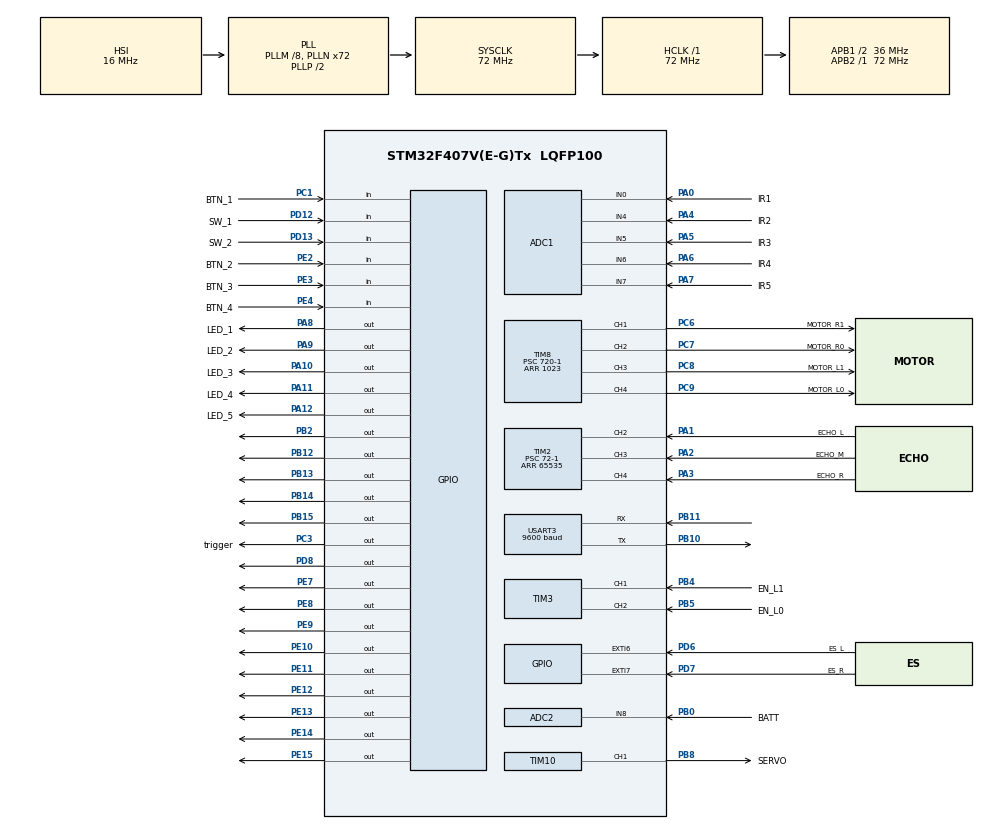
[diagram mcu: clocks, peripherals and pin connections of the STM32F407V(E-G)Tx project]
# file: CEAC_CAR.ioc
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ADC1.Channel-0\#ChannelRegularConversion=ADC_CHANNEL_0
ADC1.Channel-1\#ChannelRegularConversion=ADC_CHANNEL_4
ADC1.Channel-2\#ChannelRegularConversion=ADC_CHANNEL_5
ADC1.Channel-3\#ChannelRegularConversion=ADC_CHANNEL_6
ADC1.Channel-4\#ChannelRegularConversion=ADC_CHANNEL_7
ADC1.ContinuousConvMode=ENABLE
ADC1.NbrOfConversion=5
ADC1.NbrOfConversionFlag=1
ADC1.Rank-0\#ChannelRegularConversion=1
ADC1.Rank-1\#ChannelRegularConversion=2
ADC1.Rank-2\#ChannelRegularConversion=3
ADC1.Rank-3\#ChannelRegularConversion=4
ADC1.Rank-4\#ChannelRegularConversion=5
ADC1.SamplingTime-0\#ChannelRegularConversion=ADC_SAMPLETIME_3CYCLES
ADC1.SamplingTime-1\#ChannelRegularConversion=ADC_SAMPLETIME_3CYCLES
ADC1.SamplingTime-2\#ChannelRegularConversion=ADC_SAMPLETIME_3CYCLES
ADC1.SamplingTime-3\#ChannelRegularConversion=ADC_SAMPLETIME_3CYCLES
ADC1.SamplingTime-4\#ChannelRegularConversion=ADC_SAMPLETIME_3CYCLES
ADC1.master=1
ADC2.Channel-0\#ChannelRegularConversion=ADC_CHANNEL_8
ADC2.NbrOfConversionFlag=1
ADC2.Rank-0\#ChannelRegularConversion=1
ADC2.SamplingTime-0\#ChannelRegularConversion=ADC_SAMPLETIME_3CYCLES
Dma.ADC1.0.Direction=DMA_PERIPH_TO_MEMORY
Dma.ADC1.0.FIFOMode=DMA_FIFOMODE_DISABLE
Dma.ADC1.0.Instance=DMA2_Stream0
Dma.ADC1.0.MemDataAlignment=DMA_MDATAALIGN_HALFWORD
Dma.ADC1.0.MemInc=DMA_MINC_ENABLE
Dma.ADC1.0.Mode=DMA_CIRCULAR
Dma.ADC1.0.PeriphDataAlignment=DMA_PDATAALIGN_HALFWORD
Dma.ADC1.0.PeriphInc=DMA_PINC_DISABLE
Dma.ADC1.0.Priority=DMA_PRIORITY_LOW
Dma.Request0=ADC1
Mcu.Family=STM32F4
Mcu.Name=STM32F407V(E-G)Tx
Mcu.Package=LQFP100
NVIC.DMA2_Stream0_IRQn=true\:0\:0\:false\:false\:true\:false\:true\:true
NVIC.PriorityGroup=NVIC_PRIORITYGROUP_4
NVIC.TIM2_IRQn=true\:0\:0\:true\:false\:true\:true\:true\:true
NVIC.TIM3_IRQn=true\:0\:0\:true\:false\:true\:true\:true\:true
NVIC.TIM4_IRQn=true\:0\:0\:true\:false\:true\:true\:true\:true
NVIC.USART3_IRQn=true\:0\:0\:true\:false\:true\:true\:true\:true
PA0-WKUP.GPIO_Label=IR1
PA0-WKUP.Signal=ADCx_IN0
PA1.GPIO_Label=ECHO_L
PA1.Signal=S_TIM2_CH2
PA10.GPIO_Label=LED_3
PA10.Signal=GPIO_Output
PA11.GPIO_Label=LED_4
PA11.Signal=GPIO_Output
PA12.GPIO_Label=LED_5
PA12.Signal=GPIO_Output
PA13.Mode=Serial_Wire
PA13.Signal=SYS_JTMS-SWDIO
PA14.Mode=Serial_Wire
PA14.Signal=SYS_JTCK-SWCLK
PA2.GPIO_Label=ECHO_M
PA2.Signal=S_TIM2_CH3
PA3.GPIO_Label=ECHO_R
PA3.Signal=S_TIM2_CH4
PA4.GPIO_Label=IR2
PA4.Signal=ADCx_IN4
PA5.GPIO_Label=IR3
PA5.Signal=ADCx_IN5
PA6.GPIO_Label=IR4
PA6.Signal=ADCx_IN6
PA7.GPIO_Label=IR5
PA7.Signal=ADCx_IN7
PA8.GPIO_Label=LED_1
PA8.Signal=GPIO_Output
PA9.GPIO_Label=LED_2
PA9.Signal=GPIO_Output
PB0.GPIO_Label=BATT
PB0.Signal=ADCx_IN8
PB10.Mode=Asynchronous
PB10.Signal=USART3_TX
PB11.Mode=Asynchronous
PB11.Signal=USART3_RX
PB12.Signal=GPIO_Output
PB13.Signal=GPIO_Output
PB14.Signal=GPIO_Output
PB15.Signal=GPIO_Output
PB2.Signal=GPIO_Output
PB4.GPIO_Label=EN_L1
PB4.Signal=S_TIM3_CH1
PB5.GPIO_Label=EN_L0
PB5.Signal=S_TIM3_CH2
PB8.GPIO_Label=SERVO
PB8.Signal=S_TIM10_CH1
PC1.GPIO_Label=BTN_1
PC1.Signal=GPIO_Input
PC3.GPIO_Label=trigger
PC3.Signal=GPIO_Output
PC6.GPIO_Label=MOTOR_R1
PC6.Signal=S_TIM8_CH1
PC7.GPIO_Label=MOTOR_R0
PC7.Signal=S_TIM8_CH2
PC8.GPIO_Label=MOTOR_L1
PC8.Signal=S_TIM8_CH3
PC9.GPIO_Label=MOTOR_L0
PC9.Signal=S_TIM8_CH4
PD12.GPIO_Label=SW_1
PD12.Signal=GPIO_Input
PD13.GPIO_Label=SW_2
PD13.Signal=GPIO_Input
PD6.GPIO_Label=ES_L
PD6.Signal=GPXTI6
PD7.GPIO_Label=ES_R
PD7.Signal=GPXTI7
PD8.Signal=GPIO_Output
PE10.Signal=GPIO_Output
PE11.Signal=GPIO_Output
PE12.Signal=GPIO_Output
PE13.Signal=GPIO_Output
PE14.Signal=GPIO_Output
PE15.Signal=GPIO_Output
PE2.GPIO_Label=BTN_2
PE2.Signal=GPIO_Input
PE3.GPIO_Label=BTN_3
PE3.Signal=GPIO_Input
PE4.GPIO_Label=BTN_4
PE4.Signal=GPIO_Input
PE7.Signal=GPIO_Output
PE8.Signal=GPIO_Output
PE9.Signal=GPIO_Output
PH0-OSC_IN.Mode=HSE-External-Oscillator
PH0-OSC_IN.Signal=RCC_OSC_IN
PH1-OSC_OUT.Mode=HSE-External-Oscillator
PH1-OSC_OUT.Signal=RCC_OSC_OUT
ProjectManager.HeapSize=0x200
ProjectManager.StackSize=0x400
ProjectManager.TargetToolchain=STM32CubeIDE
RCC.48MHZClocksFreq_Value=36000000
RCC.AHBFreq_Value=72000000
RCC.APB1CLKDivider=RCC_HCLK_DIV2
RCC.APB1Freq_Value=36000000
RCC.APB1TimFreq_Value=72000000
RCC.APB2Freq_Value=72000000
RCC.APB2TimFreq_Value=72000000
RCC.CortexFreq_Value=72000000
RCC.HCLKFreq_Value=72000000
RCC.HSE_VALUE=25000000
RCC.HSI_VALUE=16000000
RCC.LSE_VALUE=32768
RCC.PLLM=8
RCC.PLLN=72
RCC.SYSCLKFreq_VALUE=72000000
RCC.SYSCLKSource=RCC_SYSCLKSOURCE_PLLCLK
RCC.VCOOutputFreq_Value=144000000
SH.ADCx_IN0.0=ADC1_IN0,IN0
SH.ADCx_IN4.0=ADC1_IN4,IN4
SH.ADCx_IN5.0=ADC1_IN5,IN5
SH.ADCx_IN6.0=ADC1_IN6,IN6
SH.ADCx_IN7.0=ADC1_IN7,IN7
SH.ADCx_IN8.0=ADC2_IN8,IN8
SH.S_TIM10_CH1.0=TIM10_CH1,PWM Generation1 CH1
SH.S_TIM2_CH2.0=TIM2_CH2,Input_Capture2_from_TI2
SH.S_TIM2_CH3.0=TIM2_CH3,Input_Capture3_from_TI3
SH.S_TIM2_CH4.0=TIM2_CH4,Input_Capture4_from_TI4
SH.S_TIM3_CH1.0=TIM3_CH1,Encoder_Interface
SH.S_TIM3_CH2.0=TIM3_CH2,Encoder_Interface
SH.S_TIM8_CH1.0=TIM8_CH1,PWM Generation1 CH1
SH.S_TIM8_CH2.0=TIM8_CH2,PWM Generation2 CH2
SH.S_TIM8_CH3.0=TIM8_CH3,PWM Generation3 CH3
SH.S_TIM8_CH4.0=TIM8_CH4,PWM Generation4 CH4
TIM10.Channel=TIM_CHANNEL_1
TIM10.Period=9999
TIM10.Prescaler=144-1
TIM10.Pulse=749
TIM2.Channel-Input_Capture2_from_TI2=TIM_CHANNEL_2
TIM2.Channel-Input_Capture3_from_TI3=TIM_CHANNEL_3
TIM2.Channel-Input_Capture4_from_TI4=TIM_CHANNEL_4
TIM2.Period=65535
TIM2.Prescaler=72-1
TIM4.Period=100-1
TIM4.Prescaler=720-1
TIM8.Channel-PWM\ Generation1\ CH1=TIM_CHANNEL_1
TIM8.Channel-PWM\ Generation2\ CH2=TIM_CHANNEL_2
TIM8.Channel-PWM\ Generation3\ CH3=TIM_CHANNEL_3
TIM8.Channel-PWM\ Generation4\ CH4=TIM_CHANNEL_4
TIM8.Period=1023
TIM8.Prescaler=720-1
TIM8.Pulse-PWM\ Generation1\ CH1=100
TIM8.Pulse-PWM\ Generation2\ CH2=100
TIM8.Pulse-PWM\ Generation3\ CH3=100
TIM8.Pulse-PWM\ Generation4\ CH4=100
USART3.BaudRate=9600
USART3.VirtualMode=VM_ASYNC
VP_TIM10_VS_ClockSourceINT.Mode=Enable_Timer
VP_TIM2_VS_ClockSourceINT.Mode=Internal
VP_TIM4_VS_ClockSourceINT.Mode=Internal
VP_TIM8_VS_ClockSourceINT.Mode=Internal
board=custom

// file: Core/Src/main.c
/* USER CODE BEGIN Header */
/**
 ******************************************************************************
 * @file           : main.c
 * @brief          : Main program body
 ******************************************************************************
 * @attention
 *
 * Copyright (c) 2024 STMicroelectronics.
 * All rights reserved.
 *
 * This software is licensed under terms that can be found in the LICENSE file
 * in the root directory of this software component.
 * If no LICENSE file comes with this software, it is provided AS-IS.
 *
 ******************************************************************************
 */
/* USER CODE END Header */
#include "main.h"

ADC_HandleTypeDef hadc1;
ADC_HandleTypeDef hadc2;
DMA_HandleTypeDef hdma_adc1;

TIM_HandleTypeDef htim2;
TIM_HandleTypeDef htim3;
TIM_HandleTypeDef htim4;
TIM_HandleTypeDef htim8;
TIM_HandleTypeDef htim10;

UART_HandleTypeDef huart3;

void SystemClock_Config(void);
static void MX_GPIO_Init(void);
static void MX_DMA_Init(void);
static void MX_TIM3_Init(void);
static void MX_TIM8_Init(void);
static void MX_ADC1_Init(void);
static void MX_ADC2_Init(void);
static void MX_TIM2_Init(void);
static void MX_TIM10_Init(void);
static void MX_TIM4_Init(void);
static void MX_USART3_UART_Init(void);

int main(void)
{

  /* MCU Configuration--------------------------------------------------------*/

  /* Reset of all peripherals, Initializes the Flash interface and the Systick. */
  HAL_Init();

  /* Configure the system clock */
  SystemClock_Config();

  /* Initialize all configured peripherals */
  MX_GPIO_Init();
  MX_DMA_Init();
  MX_TIM3_Init();
  MX_TIM8_Init();
  MX_ADC1_Init();
  MX_ADC2_Init();
  MX_TIM2_Init();
  MX_TIM10_Init();
  MX_TIM4_Init();
  MX_USART3_UART_Init();
  /* USER CODE BEGIN 2 */
  HAL_TIM_Base_Start_IT(&htim4);
  Scheduler_Init();
  Scheduler_Add_Task(&init_system, 0, 100);
  /* USER CODE END 2 */

  /* Infinite loop */
  while (1)
  {
    Scheduler_Dispatch_Tasks();
  }
}

void SystemClock_Config(void)
{
  RCC_OscInitTypeDef RCC_OscInitStruct = {0};
  RCC_ClkInitTypeDef RCC_ClkInitStruct = {0};

  /** Configure the main internal regulator output voltage
  */
  __HAL_RCC_PWR_CLK_ENABLE();
  __HAL_PWR_VOLTAGESCALING_CONFIG(PWR_REGULATOR_VOLTAGE_SCALE1);

  /** Initializes the RCC Oscillators according to the specified parameters
  * in the RCC_OscInitTypeDef structure.
  */
  RCC_OscInitStruct.OscillatorType = RCC_OSCILLATORTYPE_HSI;
  RCC_OscInitStruct.HSIState = RCC_HSI_ON;
  RCC_OscInitStruct.HSICalibrationValue = RCC_HSICALIBRATION_DEFAULT;
  RCC_OscInitStruct.PLL.PLLState = RCC_PLL_ON;
  RCC_OscInitStruct.PLL.PLLSource = RCC_PLLSOURCE_HSI;
  RCC_OscInitStruct.PLL.PLLM = 8;
  RCC_OscInitStruct.PLL.PLLN = 72;
  RCC_OscInitStruct.PLL.PLLP = RCC_PLLP_DIV2;
  RCC_OscInitStruct.PLL.PLLQ = 4;
  if (HAL_RCC_OscConfig(&RCC_OscInitStruct) != HAL_OK)
  {
    Error_Handler();
  }

  /** Initializes the CPU, AHB and APB buses clocks
  */
  RCC_ClkInitStruct.ClockType = RCC_CLOCKTYPE_HCLK|RCC_CLOCKTYPE_SYSCLK
                              |RCC_CLOCKTYPE_PCLK1|RCC_CLOCKTYPE_PCLK2;
  RCC_ClkInitStruct.SYSCLKSource = RCC_SYSCLKSOURCE_PLLCLK;
  RCC_ClkInitStruct.AHBCLKDivider = RCC_SYSCLK_DIV1;
  RCC_ClkInitStruct.APB1CLKDivider = RCC_HCLK_DIV2;
  RCC_ClkInitStruct.APB2CLKDivider = RCC_HCLK_DIV1;

  if (HAL_RCC_ClockConfig(&RCC_ClkInitStruct, FLASH_LATENCY_2) != HAL_OK)
  {
    Error_Handler();
  }
}

static void MX_ADC1_Init(void)
{

  ADC_ChannelConfTypeDef sConfig = {0};

  /** Configure the global features of the ADC (Clock, Resolution, Data Alignment and number of conversion)
  */
  hadc1.Instance = ADC1;
  hadc1.Init.ClockPrescaler = ADC_CLOCK_SYNC_PCLK_DIV2;
  hadc1.Init.Resolution = ADC_RESOLUTION_12B;
  hadc1.Init.ScanConvMode = ENABLE;
  hadc1.Init.ContinuousConvMode = ENABLE;
  hadc1.Init.DiscontinuousConvMode = DISABLE;
  hadc1.Init.ExternalTrigConvEdge = ADC_EXTERNALTRIGCONVEDGE_NONE;
  hadc1.Init.ExternalTrigConv = ADC_SOFTWARE_START;
  hadc1.Init.DataAlign = ADC_DATAALIGN_RIGHT;
  hadc1.Init.NbrOfConversion = 5;
  hadc1.Init.DMAContinuousRequests = DISABLE;
  hadc1.Init.EOCSelection = ADC_EOC_SINGLE_CONV;
  if (HAL_ADC_Init(&hadc1) != HAL_OK)
  {
    Error_Handler();
  }

  /** Configure for the selected ADC regular channel its corresponding rank in the sequencer and its sample time.
  */
  sConfig.Channel = ADC_CHANNEL_0;
  sConfig.Rank = 1;
  sConfig.SamplingTime = ADC_SAMPLETIME_3CYCLES;
  if (HAL_ADC_ConfigChannel(&hadc1, &sConfig) != HAL_OK)
  {
    Error_Handler();
  }

  /** Configure for the selected ADC regular channel its corresponding rank in the sequencer and its sample time.
  */
  sConfig.Channel = ADC_CHANNEL_4;
  sConfig.Rank = 2;
  if (HAL_ADC_ConfigChannel(&hadc1, &sConfig) != HAL_OK)
  {
    Error_Handler();
  }

  /** Configure for the selected ADC regular channel its corresponding rank in the sequencer and its sample time.
  */
  sConfig.Channel = ADC_CHANNEL_5;
  sConfig.Rank = 3;
  if (HAL_ADC_ConfigChannel(&hadc1, &sConfig) != HAL_OK)
  {
    Error_Handler();
  }

  /** Configure for the selected ADC regular channel its corresponding rank in the sequencer and its sample time.
  */
  sConfig.Channel = ADC_CHANNEL_6;
  sConfig.Rank = 4;
  if (HAL_ADC_ConfigChannel(&hadc1, &sConfig) != HAL_OK)
  {
    Error_Handler();
  }

  /** Configure for the selected ADC regular channel its corresponding rank in the sequencer and its sample time.
  */
  sConfig.Channel = ADC_CHANNEL_7;
  sConfig.Rank = 5;
  if (HAL_ADC_ConfigChannel(&hadc1, &sConfig) != HAL_OK)
  {
    Error_Handler();
  }

}

static void MX_ADC2_Init(void)
{

  ADC_ChannelConfTypeDef sConfig = {0};

  /** Configure the global features of the ADC (Clock, Resolution, Data Alignment and number of conversion)
  */
  hadc2.Instance = ADC2;
  hadc2.Init.ClockPrescaler = ADC_CLOCK_SYNC_PCLK_DIV2;
  hadc2.Init.Resolution = ADC_RESOLUTION_12B;
  hadc2.Init.ScanConvMode = DISABLE;
  hadc2.Init.ContinuousConvMode = DISABLE;
  hadc2.Init.DiscontinuousConvMode = DISABLE;
  hadc2.Init.ExternalTrigConvEdge = ADC_EXTERNALTRIGCONVEDGE_NONE;
  hadc2.Init.ExternalTrigConv = ADC_SOFTWARE_START;
  hadc2.Init.DataAlign = ADC_DATAALIGN_RIGHT;
  hadc2.Init.NbrOfConversion = 1;
  hadc2.Init.DMAContinuousRequests = DISABLE;
  hadc2.Init.EOCSelection = ADC_EOC_SINGLE_CONV;
  if (HAL_ADC_Init(&hadc2) != HAL_OK)
  {
    Error_Handler();
  }

  /** Configure for the selected ADC regular channel its corresponding rank in the sequencer and its sample time.
  */
  sConfig.Channel = ADC_CHANNEL_8;
  sConfig.Rank = 1;
  sConfig.SamplingTime = ADC_SAMPLETIME_3CYCLES;
  if (HAL_ADC_ConfigChannel(&hadc2, &sConfig) != HAL_OK)
  {
    Error_Handler();
  }

}

static void MX_TIM2_Init(void)
{

  TIM_ClockConfigTypeDef sClockSourceConfig = {0};
  TIM_MasterConfigTypeDef sMasterConfig = {0};
  TIM_IC_InitTypeDef sConfigIC = {0};

  htim2.Instance = TIM2;
  htim2.Init.Prescaler = 72-1;
  htim2.Init.CounterMode = TIM_COUNTERMODE_UP;
  htim2.Init.Period = 65535;
  htim2.Init.ClockDivision = TIM_CLOCKDIVISION_DIV1;
  htim2.Init.AutoReloadPreload = TIM_AUTORELOAD_PRELOAD_DISABLE;
  if (HAL_TIM_Base_Init(&htim2) != HAL_OK)
  {
    Error_Handler();
  }
  sClockSourceConfig.ClockSource = TIM_CLOCKSOURCE_INTERNAL;
  if (HAL_TIM_ConfigClockSource(&htim2, &sClockSourceConfig) != HAL_OK)
  {
    Error_Handler();
  }
  if (HAL_TIM_IC_Init(&htim2) != HAL_OK)
  {
    Error_Handler();
  }
  sMasterConfig.MasterOutputTrigger = TIM_TRGO_RESET;
  sMasterConfig.MasterSlaveMode = TIM_MASTERSLAVEMODE_DISABLE;
  if (HAL_TIMEx_MasterConfigSynchronization(&htim2, &sMasterConfig) != HAL_OK)
  {
    Error_Handler();
  }
  sConfigIC.ICPolarity = TIM_INPUTCHANNELPOLARITY_RISING;
  sConfigIC.ICSelection = TIM_ICSELECTION_DIRECTTI;
  sConfigIC.ICPrescaler = TIM_ICPSC_DIV1;
  sConfigIC.ICFilter = 0;
  if (HAL_TIM_IC_ConfigChannel(&htim2, &sConfigIC, TIM_CHANNEL_2) != HAL_OK)
  {
    Error_Handler();
  }
  if (HAL_TIM_IC_ConfigChannel(&htim2, &sConfigIC, TIM_CHANNEL_3) != HAL_OK)
  {
    Error_Handler();
  }
  if (HAL_TIM_IC_ConfigChannel(&htim2, &sConfigIC, TIM_CHANNEL_4) != HAL_OK)
  {
    Error_Handler();
  }

}

static void MX_TIM3_Init(void)
{

  TIM_Encoder_InitTypeDef sConfig = {0};
  TIM_MasterConfigTypeDef sMasterConfig = {0};

  htim3.Instance = TIM3;
  htim3.Init.Prescaler = 0;
  htim3.Init.CounterMode = TIM_COUNTERMODE_UP;
  htim3.Init.Period = 65535;
  htim3.Init.ClockDivision = TIM_CLOCKDIVISION_DIV1;
  htim3.Init.AutoReloadPreload = TIM_AUTORELOAD_PRELOAD_DISABLE;
  sConfig.EncoderMode = TIM_ENCODERMODE_TI1;
  sConfig.IC1Polarity = TIM_ICPOLARITY_RISING;
  sConfig.IC1Selection = TIM_ICSELECTION_DIRECTTI;
  sConfig.IC1Prescaler = TIM_ICPSC_DIV1;
  sConfig.IC1Filter = 0;
  sConfig.IC2Polarity = TIM_ICPOLARITY_RISING;
  sConfig.IC2Selection = TIM_ICSELECTION_DIRECTTI;
  sConfig.IC2Prescaler = TIM_ICPSC_DIV1;
  sConfig.IC2Filter = 0;
  if (HAL_TIM_Encoder_Init(&htim3, &sConfig) != HAL_OK)
  {
    Error_Handler();
  }
  sMasterConfig.MasterOutputTrigger = TIM_TRGO_RESET;
  sMasterConfig.MasterSlaveMode = TIM_MASTERSLAVEMODE_DISABLE;
  if (HAL_TIMEx_MasterConfigSynchronization(&htim3, &sMasterConfig) != HAL_OK)
  {
    Error_Handler();
  }

}

static void MX_TIM4_Init(void)
{

  TIM_ClockConfigTypeDef sClockSourceConfig = {0};
  TIM_MasterConfigTypeDef sMasterConfig = {0};

  htim4.Instance = TIM4;
  htim4.Init.Prescaler = 720-1;
  htim4.Init.CounterMode = TIM_COUNTERMODE_UP;
  htim4.Init.Period = 100-1;
  htim4.Init.ClockDivision = TIM_CLOCKDIVISION_DIV1;
  htim4.Init.AutoReloadPreload = TIM_AUTORELOAD_PRELOAD_DISABLE;
  if (HAL_TIM_Base_Init(&htim4) != HAL_OK)
  {
    Error_Handler();
  }
  sClockSourceConfig.ClockSource = TIM_CLOCKSOURCE_INTERNAL;
  if (HAL_TIM_ConfigClockSource(&htim4, &sClockSourceConfig) != HAL_OK)
  {
    Error_Handler();
  }
  sMasterConfig.MasterOutputTrigger = TIM_TRGO_RESET;
  sMasterConfig.MasterSlaveMode = TIM_MASTERSLAVEMODE_DISABLE;
  if (HAL_TIMEx_MasterConfigSynchronization(&htim4, &sMasterConfig) != HAL_OK)
  {
    Error_Handler();
  }

}

static void MX_TIM8_Init(void)
{

  TIM_ClockConfigTypeDef sClockSourceConfig = {0};
  TIM_MasterConfigTypeDef sMasterConfig = {0};
  TIM_OC_InitTypeDef sConfigOC = {0};
  TIM_BreakDeadTimeConfigTypeDef sBreakDeadTimeConfig = {0};

  htim8.Instance = TIM8;
  htim8.Init.Prescaler = 720-1;
  htim8.Init.CounterMode = TIM_COUNTERMODE_UP;
  htim8.Init.Period = 1023;
  htim8.Init.ClockDivision = TIM_CLOCKDIVISION_DIV1;
  htim8.Init.RepetitionCounter = 0;
  htim8.Init.AutoReloadPreload = TIM_AUTORELOAD_PRELOAD_DISABLE;
  if (HAL_TIM_Base_Init(&htim8) != HAL_OK)
  {
    Error_Handler();
  }
  sClockSourceConfig.ClockSource = TIM_CLOCKSOURCE_INTERNAL;
  if (HAL_TIM_ConfigClockSource(&htim8, &sClockSourceConfig) != HAL_OK)
  {
    Error_Handler();
  }
  if (HAL_TIM_PWM_Init(&htim8) != HAL_OK)
  {
    Error_Handler();
  }
  sMasterConfig.MasterOutputTrigger = TIM_TRGO_RESET;
  sMasterConfig.MasterSlaveMode = TIM_MASTERSLAVEMODE_DISABLE;
  if (HAL_TIMEx_MasterConfigSynchronization(&htim8, &sMasterConfig) != HAL_OK)
  {
    Error_Handler();
  }
  sConfigOC.OCMode = TIM_OCMODE_PWM1;
  sConfigOC.Pulse = 100;
  sConfigOC.OCPolarity = TIM_OCPOLARITY_HIGH;
  sConfigOC.OCNPolarity = TIM_OCNPOLARITY_HIGH;
  sConfigOC.OCFastMode = TIM_OCFAST_DISABLE;
  sConfigOC.OCIdleState = TIM_OCIDLESTATE_RESET;
  sConfigOC.OCNIdleState = TIM_OCNIDLESTATE_RESET;
  if (HAL_TIM_PWM_ConfigChannel(&htim8, &sConfigOC, TIM_CHANNEL_1) != HAL_OK)
  {
    Error_Handler();
  }
  if (HAL_TIM_PWM_ConfigChannel(&htim8, &sConfigOC, TIM_CHANNEL_2) != HAL_OK)
  {
    Error_Handler();
  }
  if (HAL_TIM_PWM_ConfigChannel(&htim8, &sConfigOC, TIM_CHANNEL_3) != HAL_OK)
  {
    Error_Handler();
  }
  if (HAL_TIM_PWM_ConfigChannel(&htim8, &sConfigOC, TIM_CHANNEL_4) != HAL_OK)
  {
    Error_Handler();
  }
  sBreakDeadTimeConfig.OffStateRunMode = TIM_OSSR_DISABLE;
  sBreakDeadTimeConfig.OffStateIDLEMode = TIM_OSSI_DISABLE;
  sBreakDeadTimeConfig.LockLevel = TIM_LOCKLEVEL_OFF;
  sBreakDeadTimeConfig.DeadTime = 0;
  sBreakDeadTimeConfig.BreakState = TIM_BREAK_DISABLE;
  sBreakDeadTimeConfig.BreakPolarity = TIM_BREAKPOLARITY_HIGH;
  sBreakDeadTimeConfig.AutomaticOutput = TIM_AUTOMATICOUTPUT_DISABLE;
  if (HAL_TIMEx_ConfigBreakDeadTime(&htim8, &sBreakDeadTimeConfig) != HAL_OK)
  {
    Error_Handler();
  }
  HAL_TIM_MspPostInit(&htim8);

}

static void MX_TIM10_Init(void)
{

  TIM_OC_InitTypeDef sConfigOC = {0};

  htim10.Instance = TIM10;
  htim10.Init.Prescaler = 144-1;
  htim10.Init.CounterMode = TIM_COUNTERMODE_UP;
  htim10.Init.Period = 9999;
  htim10.Init.ClockDivision = TIM_CLOCKDIVISION_DIV1;
  htim10.Init.AutoReloadPreload = TIM_AUTORELOAD_PRELOAD_DISABLE;
  if (HAL_TIM_Base_Init(&htim10) != HAL_OK)
  {
    Error_Handler();
  }
  if (HAL_TIM_PWM_Init(&htim10) != HAL_OK)
  {
    Error_Handler();
  }
  sConfigOC.OCMode = TIM_OCMODE_PWM1;
  sConfigOC.Pulse = 749;
  sConfigOC.OCPolarity = TIM_OCPOLARITY_HIGH;
  sConfigOC.OCFastMode = TIM_OCFAST_DISABLE;
  if (HAL_TIM_PWM_ConfigChannel(&htim10, &sConfigOC, TIM_CHANNEL_1) != HAL_OK)
  {
    Error_Handler();
  }
  HAL_TIM_MspPostInit(&htim10);

}

static void MX_USART3_UART_Init(void)
{

  huart3.Instance = USART3;
  huart3.Init.BaudRate = 9600;
  huart3.Init.WordLength = UART_WORDLENGTH_8B;
  huart3.Init.StopBits = UART_STOPBITS_1;
  huart3.Init.Parity = UART_PARITY_NONE;
  huart3.Init.Mode = UART_MODE_TX_RX;
  huart3.Init.HwFlowCtl = UART_HWCONTROL_NONE;
  huart3.Init.OverSampling = UART_OVERSAMPLING_16;
  if (HAL_UART_Init(&huart3) != HAL_OK)
  {
    Error_Handler();
  }

}

static void MX_DMA_Init(void)
{

  /* DMA controller clock enable */
  __HAL_RCC_DMA2_CLK_ENABLE();

  /* DMA interrupt init */
  /* DMA2_Stream0_IRQn interrupt configuration */
  HAL_NVIC_SetPriority(DMA2_Stream0_IRQn, 0, 0);
  HAL_NVIC_EnableIRQ(DMA2_Stream0_IRQn);

}

static void MX_GPIO_Init(void)
{
  GPIO_InitTypeDef GPIO_InitStruct = {0};

  /* GPIO Ports Clock Enable */
  __HAL_RCC_GPIOE_CLK_ENABLE();
  __HAL_RCC_GPIOH_CLK_ENABLE();
  __HAL_RCC_GPIOC_CLK_ENABLE();
  __HAL_RCC_GPIOA_CLK_ENABLE();
  __HAL_RCC_GPIOB_CLK_ENABLE();
  __HAL_RCC_GPIOD_CLK_ENABLE();

  /*Configure GPIO pin Output Level */
  HAL_GPIO_WritePin(trigger_GPIO_Port, trigger_Pin, GPIO_PIN_RESET);

  /*Configure GPIO pin Output Level */
  HAL_GPIO_WritePin(GPIOB, GPIO_PIN_2|GPIO_PIN_12|GPIO_PIN_13|GPIO_PIN_14
                          |GPIO_PIN_15, GPIO_PIN_RESET);

  /*Configure GPIO pin Output Level */
  HAL_GPIO_WritePin(GPIOE, GPIO_PIN_7|GPIO_PIN_8|GPIO_PIN_9|GPIO_PIN_10
                          |GPIO_PIN_11|GPIO_PIN_12|GPIO_PIN_13|GPIO_PIN_14
                          |GPIO_PIN_15, GPIO_PIN_RESET);

  /*Configure GPIO pin Output Level */
  HAL_GPIO_WritePin(GPIOD, GPIO_PIN_8, GPIO_PIN_RESET);

  /*Configure GPIO pin Output Level */
  HAL_GPIO_WritePin(GPIOA, LED_1_Pin|LED_2_Pin|LED_3_Pin|LED_4_Pin
                          |LED_5_Pin, GPIO_PIN_RESET);

  /*Configure GPIO pins : BTN_2_Pin BTN_3_Pin BTN_4_Pin */
  GPIO_InitStruct.Pin = BTN_2_Pin|BTN_3_Pin|BTN_4_Pin;
  GPIO_InitStruct.Mode = GPIO_MODE_INPUT;
  GPIO_InitStruct.Pull = GPIO_NOPULL;
  HAL_GPIO_Init(GPIOE, &GPIO_InitStruct);

  /*Configure GPIO pin : BTN_1_Pin */
  GPIO_InitStruct.Pin = BTN_1_Pin;
  GPIO_InitStruct.Mode = GPIO_MODE_INPUT;
  GPIO_InitStruct.Pull = GPIO_NOPULL;
  HAL_GPIO_Init(BTN_1_GPIO_Port, &GPIO_InitStruct);

  /*Configure GPIO pin : trigger_Pin */
  GPIO_InitStruct.Pin = trigger_Pin;
  GPIO_InitStruct.Mode = GPIO_MODE_OUTPUT_PP;
  GPIO_InitStruct.Pull = GPIO_NOPULL;
  GPIO_InitStruct.Speed = GPIO_SPEED_FREQ_LOW;
  HAL_GPIO_Init(trigger_GPIO_Port, &GPIO_InitStruct);

  /*Configure GPIO pins : PB2 PB12 PB13 PB14
                           PB15 */
  GPIO_InitStruct.Pin = GPIO_PIN_2|GPIO_PIN_12|GPIO_PIN_13|GPIO_PIN_14
                          |GPIO_PIN_15;
  GPIO_InitStruct.Mode = GPIO_MODE_OUTPUT_PP;
  GPIO_InitStruct.Pull = GPIO_NOPULL;
  GPIO_InitStruct.Speed = GPIO_SPEED_FREQ_LOW;
  HAL_GPIO_Init(GPIOB, &GPIO_InitStruct);

  /*Configure GPIO pins : PE7 PE8 PE9 PE10
                           PE11 PE12 PE13 PE14
                           PE15 */
  GPIO_InitStruct.Pin = GPIO_PIN_7|GPIO_PIN_8|GPIO_PIN_9|GPIO_PIN_10
                          |GPIO_PIN_11|GPIO_PIN_12|GPIO_PIN_13|GPIO_PIN_14
                          |GPIO_PIN_15;
  GPIO_InitStruct.Mode = GPIO_MODE_OUTPUT_PP;
  GPIO_InitStruct.Pull = GPIO_NOPULL;
  GPIO_InitStruct.Speed = GPIO_SPEED_FREQ_LOW;
  HAL_GPIO_Init(GPIOE, &GPIO_InitStruct);

  /*Configure GPIO pin : PD8 */
  GPIO_InitStruct.Pin = GPIO_PIN_8;
  GPIO_InitStruct.Mode = GPIO_MODE_OUTPUT_PP;
  GPIO_InitStruct.Pull = GPIO_NOPULL;
  GPIO_InitStruct.Speed = GPIO_SPEED_FREQ_LOW;
  HAL_GPIO_Init(GPIOD, &GPIO_InitStruct);

  /*Configure GPIO pins : SW_1_Pin SW_2_Pin */
  GPIO_InitStruct.Pin = SW_1_Pin|SW_2_Pin;
  GPIO_InitStruct.Mode = GPIO_MODE_INPUT;
  GPIO_InitStruct.Pull = GPIO_NOPULL;
  HAL_GPIO_Init(GPIOD, &GPIO_InitStruct);

  /*Configure GPIO pins : LED_1_Pin LED_2_Pin LED_3_Pin LED_4_Pin
                           LED_5_Pin */
  GPIO_InitStruct.Pin = LED_1_Pin|LED_2_Pin|LED_3_Pin|LED_4_Pin
                          |LED_5_Pin;
  GPIO_InitStruct.Mode = GPIO_MODE_OUTPUT_PP;
  GPIO_InitStruct.Pull = GPIO_NOPULL;
  GPIO_InitStruct.Speed = GPIO_SPEED_FREQ_LOW;
  HAL_GPIO_Init(GPIOA, &GPIO_InitStruct);

  /*Configure GPIO pins : ES_L_Pin ES_R_Pin */
  GPIO_InitStruct.Pin = ES_L_Pin|ES_R_Pin;
  GPIO_InitStruct.Mode = GPIO_MODE_IT_RISING;
  GPIO_InitStruct.Pull = GPIO_NOPULL;
  HAL_GPIO_Init(GPIOD, &GPIO_InitStruct);

}

/* USER CODE BEGIN 4 */

//void HAL_UART_RxCpltCallback(UART_HandleTypeDef *huart)
//{
//  if (huart->Instance == USART3)
//  {
////    HAL_GPIO_TogglePin(LED_1_GPIO_Port, LED_1_Pin);
//	  HAL_UART_Receive_IT(&huart3, (uint8_t *)rev, sizeof(rev));
//
//  }
//}

// #if defined(TEST_ULTRASONIC) || defined(TEST_ENCODER)
void HAL_TIM_PeriodElapsedCallback(TIM_HandleTypeDef *htim)
{
  if (htim->Instance == htim4.Instance) // make sure
  {
      Scheduler_Update();
  //   activeTrigger(&sensor1);
  //   HAL_TIM_IC_Start_IT((&sensor1)->htim, TIM_CHANNEL_1);
  //   HAL_TIM_IC_Start_IT((&sensor2)->htim, TIM_CHANNEL_2);
  //   HAL_TIM_IC_Start_IT((&sensor3)->htim, TIM_CHANNEL_3);
  //   //		updateEncoder(&enc, ((TIM3->SMCR & 0x3) == 0x3));
  }
}
// #endif
// void HAL_TIM_IC_CaptureCallback(TIM_HandleTypeDef *htim)
// {
//   if (htim->Channel == HAL_TIM_ACTIVE_CHANNEL_2)
//   {
//     updateDistance(&sensor1, TIM_CHANNEL_2);
//   }
//   else if (htim->Channel == HAL_TIM_ACTIVE_CHANNEL_3)
//   {
//     updateDistance(&sensor2, TIM_CHANNEL_3);
//   }
//   else if (htim->Channel == HAL_TIM_ACTIVE_CHANNEL_4)
//   {
//     updateDistance(&sensor3, TIM_CHANNEL_4);
//   }
// }

// void SysTick_CallBack(void)
// {
//   // for example
//   //     time++;
//   //     if (time >= 270) //25ms
//   //     {
//   //         activeTrigger(&sensor);
//   //         HAL_TIM_IC_Start_IT((&sensor)->htim, TIM_CHANNEL_1);
//   //         time = 0;
//   //     }
// }
/* USER CODE END 4 */

void Error_Handler(void)
{
  __disable_irq();
  while (1)
  {
  }
}
